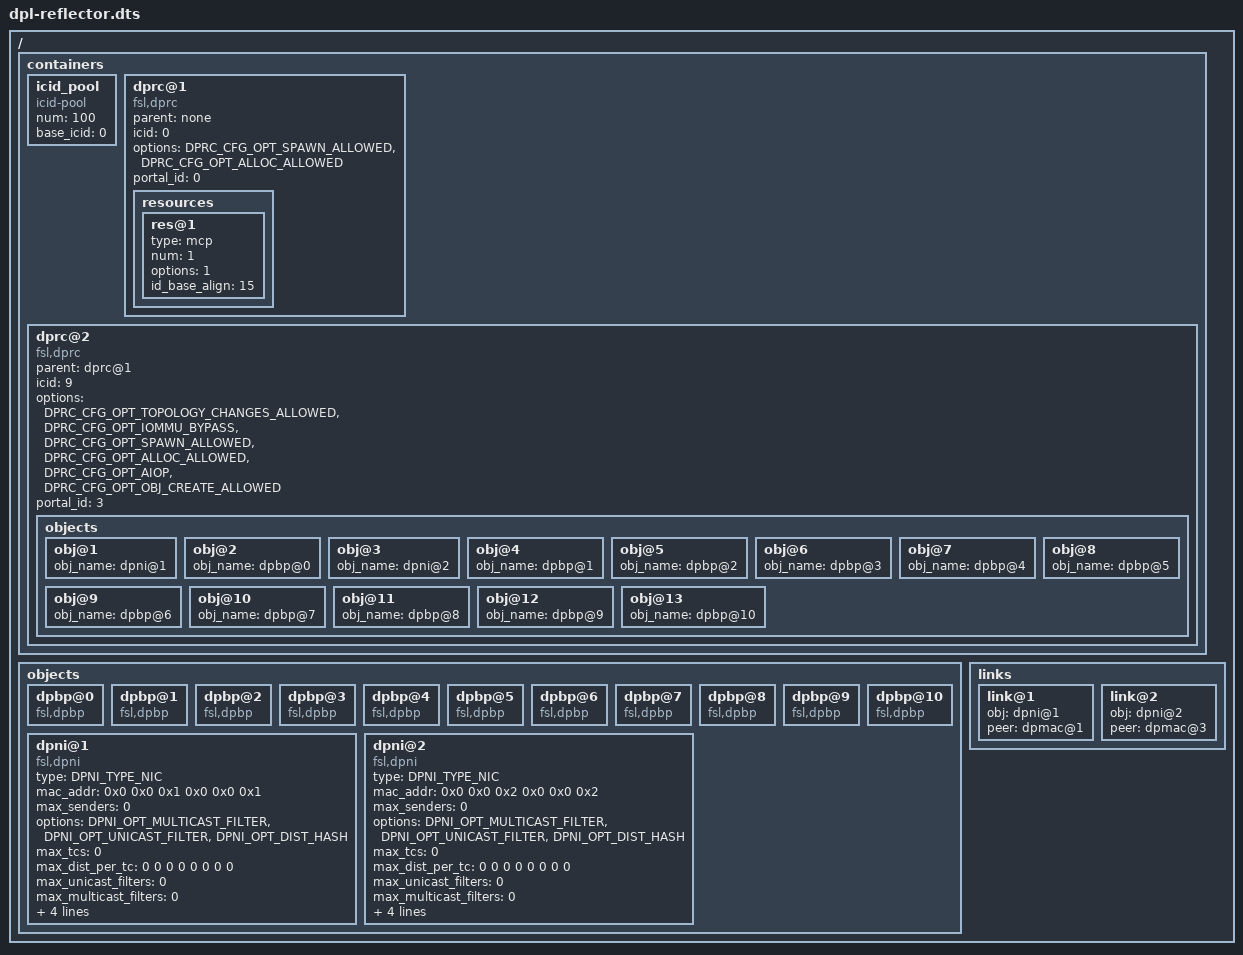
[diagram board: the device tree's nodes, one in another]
/*
 * Datapath layout file for LS2085A.
 * Contains 2 containers -- one for host Linux, one for AIOP
 *
 * Copyright 2013 Freescale Semiconductor, Inc.
 */
/dts-v1/;
/ {
	containers {
		icid_pool {
			compatible = "icid-pool";
			num = <100>;
			base_icid = <0>;
		};
		dprc@1 {
			compatible = "fsl,dprc";
			parent = "none";
			icid = <0>;
			options = "DPRC_CFG_OPT_SPAWN_ALLOWED",
					"DPRC_CFG_OPT_ALLOC_ALLOWED";
			portal_id = <0>;
			resources {
				/* Needed for restool Linux US application */
				res@1 {
					type = "mcp";
					num = <1>;
					options = <1>;
					id_base_align = <15>;
				};
			};
		};
		dprc@2 {
			compatible = "fsl,dprc";
			parent = "dprc@1";
			icid = <9>;
			options = "DPRC_CFG_OPT_TOPOLOGY_CHANGES_ALLOWED",
					"DPRC_CFG_OPT_IOMMU_BYPASS",
					"DPRC_CFG_OPT_SPAWN_ALLOWED",
					"DPRC_CFG_OPT_ALLOC_ALLOWED",
					"DPRC_CFG_OPT_AIOP",
					"DPRC_CFG_OPT_OBJ_CREATE_ALLOWED";
			portal_id = <3>;
			objects {
				obj@1{
					obj_name = "dpni@1";
				};
				obj@2{
					obj_name = "dpbp@0";
				};
				obj@3{
					obj_name = "dpni@2";
				};
				obj@4{
					obj_name = "dpbp@1";
				};
				obj@5{
					obj_name = "dpbp@2";
				};
				obj@6{
					obj_name = "dpbp@3";
				};
				obj@7{
					obj_name = "dpbp@4";
				};
				obj@8{
					obj_name = "dpbp@5";
				};
				obj@9{
					obj_name = "dpbp@6";
				};
				obj@10{
					obj_name = "dpbp@7";
				};
				obj@11{
					obj_name = "dpbp@8";
				};
				obj@12{
					obj_name = "dpbp@9";
				};
				obj@13{
					obj_name = "dpbp@10";
				};
			};
		};
	};
	objects {
		dpbp@0 {
			compatible = "fsl,dpbp";
		};
		dpbp@1 {
			compatible = "fsl,dpbp";
		};
		dpbp@2 {
			compatible = "fsl,dpbp";
		};
		dpbp@3 {
			compatible = "fsl,dpbp";
		};
		dpbp@4 {
			compatible = "fsl,dpbp";
		};
		dpbp@5 {
			compatible = "fsl,dpbp";
		};
		dpbp@6 {
			compatible = "fsl,dpbp";
		};
		dpbp@7 {
			compatible = "fsl,dpbp";
		};
		dpbp@8 {
			compatible = "fsl,dpbp";
		};
		dpbp@9 {
			compatible = "fsl,dpbp";
		};
		dpbp@10 {
			compatible = "fsl,dpbp";
		};
		dpni@1{
			compatible = "fsl,dpni";
			type = "DPNI_TYPE_NIC";
			mac_addr = < 0x0 0x0 0x1 0x0 0x0 0x1 >;
			max_senders = <0>;
			options = "DPNI_OPT_MULTICAST_FILTER",
					"DPNI_OPT_UNICAST_FILTER",
					"DPNI_OPT_DIST_HASH";
			max_tcs = <0>;
			max_dist_per_tc = < 0 0 0 0 0 0 0 0 >;
			max_unicast_filters = <0>;
			max_multicast_filters = <0>;
			max_vlan_filters = <0>;
			max_qos_entries = <0>;
			max_qos_key_size = <0>;
			max_dist_key_size = <0>;
		};
		dpni@2{
			compatible = "fsl,dpni";
			type = "DPNI_TYPE_NIC";
			mac_addr = < 0x0 0x0 0x2 0x0 0x0 0x2 >;
			max_senders = <0>;
			options = "DPNI_OPT_MULTICAST_FILTER",
					"DPNI_OPT_UNICAST_FILTER",
					"DPNI_OPT_DIST_HASH";
			max_tcs = <0>;
			max_dist_per_tc = < 0 0 0 0 0 0 0 0 >;
			max_unicast_filters = <0>;
			max_multicast_filters = <0>;
			max_vlan_filters = <0>;
			max_qos_entries = <0>;
			max_qos_key_size = <0>;
			max_dist_key_size = <0>;
		};
	};
	links {
		link@1 {
			obj = "dpni@1";
			peer = "dpmac@1";
		};
		link@2 {
			obj = "dpni@2";
			peer = "dpmac@3";
		};
	};
};
